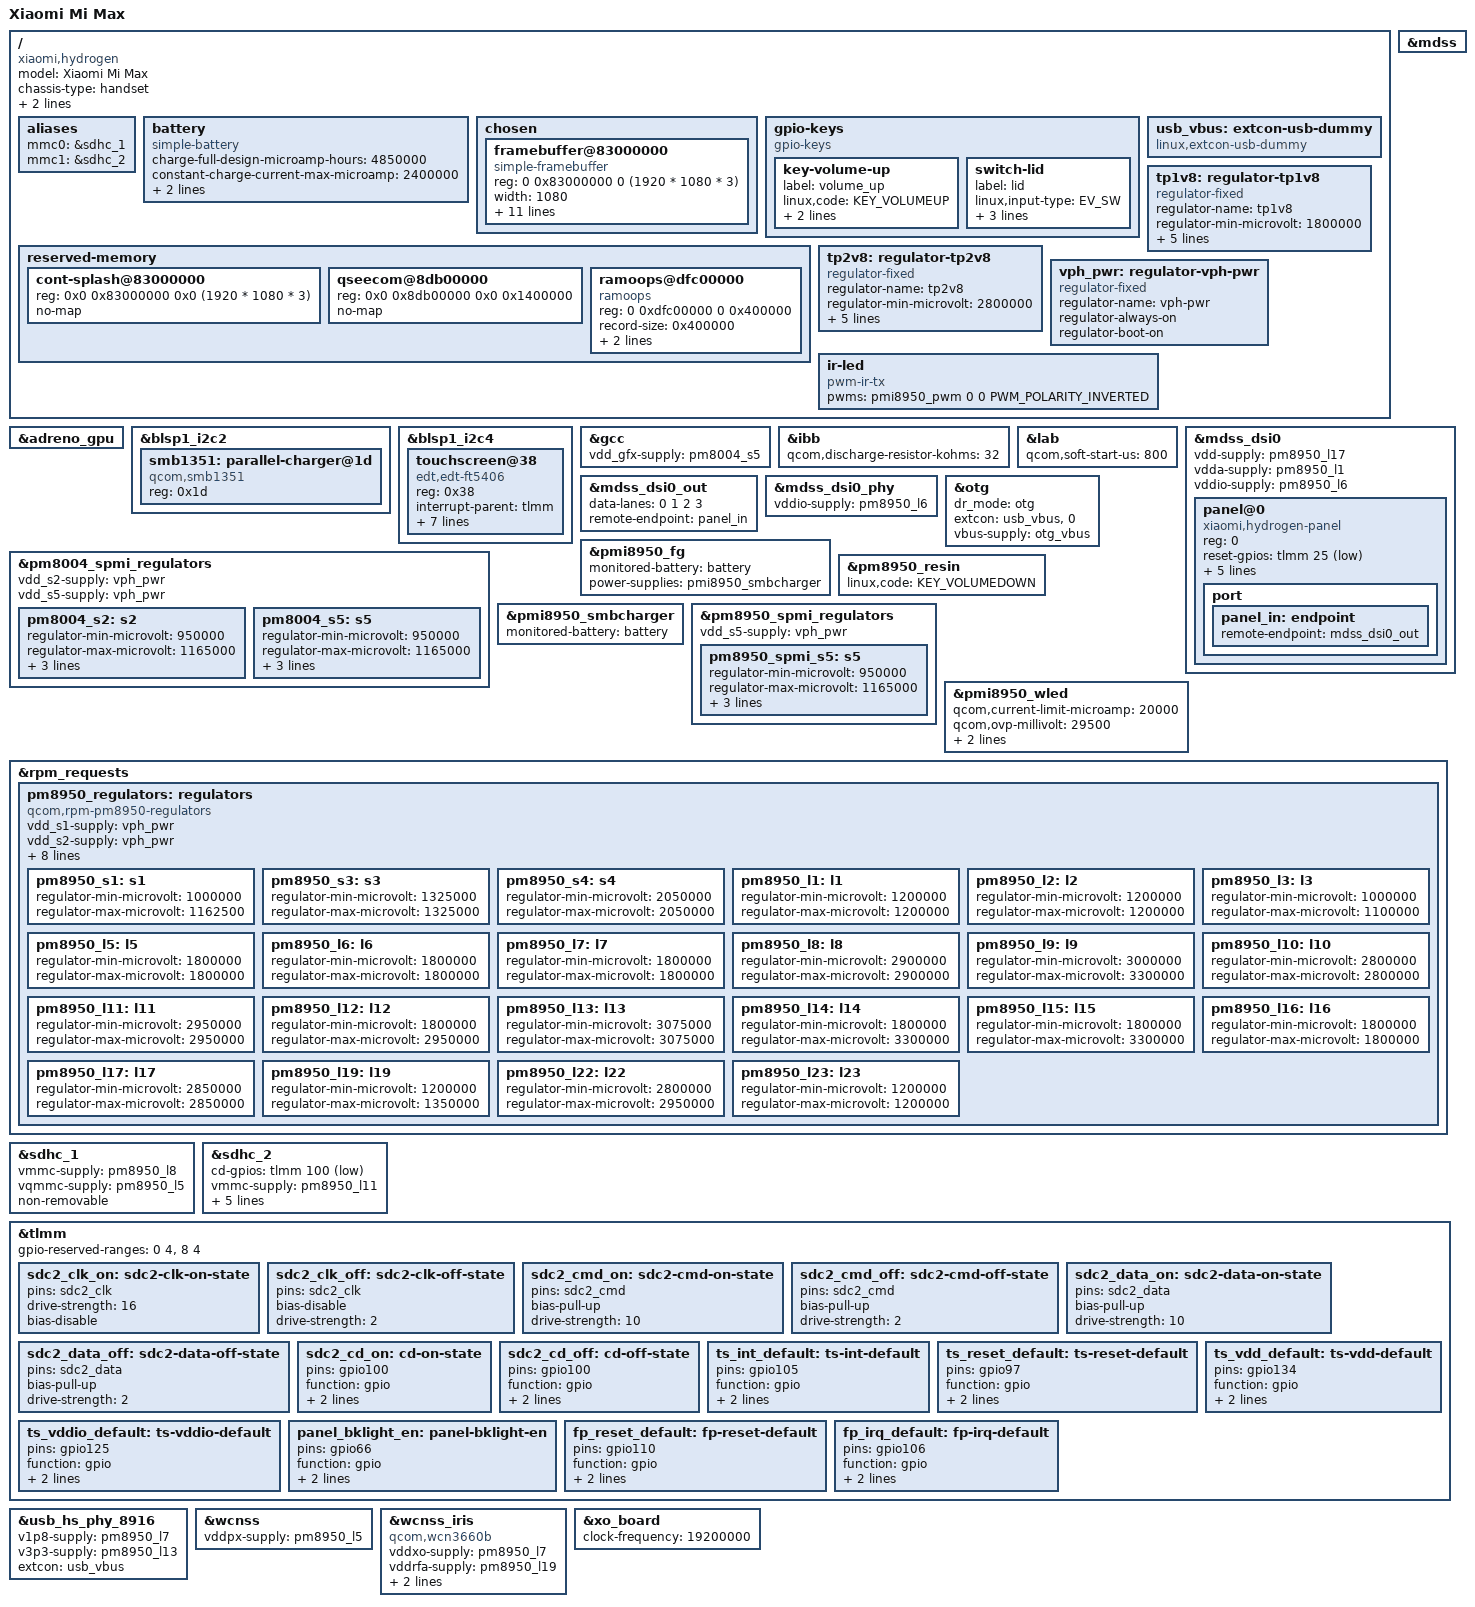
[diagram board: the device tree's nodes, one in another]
// SPDX-License-Identifier: BSD-3-Clause
/*
 * Copyright (c) 2024, Barnabas Czeman <trabarni@gmail.com>
 * Copyright (c) 2026, Jamie Chio <chioks03@gmail.com>
 *
 * Based on msm8956-xiaomi-kenzo.dts, adapted from hydrogen downstream DTS.
 *
 * Xiaomi Mi Max (hydrogen) hardware overview:
 *   - SoC: Qualcomm MSM8956 (Snapdragon 650)
 *   - PMIC: PM8950 + PMI8950 + PM8004
 *   - Display: 1080x1920 6.44" IPS (Tianma R63350 / AUO R61322)
 *   - Touch: Atmel mXT336U / FocalTech FT5x46 (I2C4)
 *   - Battery: 4850 mAh (ATL / Coslight)
 *   - Storage: eMMC + microSD
 *   - WiFi/BT: Qualcomm WCN3660b
 *   - Fingerprint: FPC FPC1020
 *   - Notification LED: Awinic AW2013 RGB (I2C8)
 *   - Hall sensor: GPIO 107
 */
/dts-v1/;

#include <dt-bindings/arm/qcom,ids.h>
#include <dt-bindings/input/atmel-maxtouch.h>
#include <dt-bindings/input/input.h>
#include <dt-bindings/pwm/pwm.h>

#include "msm8956.dtsi"

#include "pm8004.dtsi"
#include "pm8950.dtsi"
#include "pmi8950.dtsi"

/ {
	model = "Xiaomi Mi Max";
	compatible = "xiaomi,hydrogen", "qcom,msm8956";
	chassis-type = "handset";
	qcom,msm-id = <QCOM_ID_MSM8956 0x10001>;
	qcom,board-id = <QCOM_BOARD_ID_MTP 0>;

	aliases {
		mmc0 = &sdhc_1;
		mmc1 = &sdhc_2;
	};

	battery: battery {
		compatible = "simple-battery";

		/* ATL/Coslight 4850 mAh packs */
		charge-full-design-microamp-hours = <4850000>;
		constant-charge-current-max-microamp = <2400000>;
		voltage-min-design-microvolt = <3400000>;
		voltage-max-design-microvolt = <4400000>;
	};

	    chosen {
		#address-cells = <2>;
		#size-cells = <2>;
		ranges;

		/* Downstream cont_splash at 0x83000000 */
		framebuffer@83000000 {
		    compatible = "simple-framebuffer";
		    reg = <0 0x83000000 0 (1920 * 1080 * 3)>;

		    width = <1080>;
		    height = <1920>;
		    stride = <(1080 * 3)>;
		    format = "r8g8b8";

		    power-domains = <&gcc MDSS_GDSC>;

		    clocks = <&gcc GCC_MDSS_AHB_CLK>,
		         <&gcc GCC_MDSS_AXI_CLK>,
		         <&gcc GCC_MDSS_VSYNC_CLK>,
		         <&gcc GCC_MDSS_MDP_CLK>,
		         <&gcc GCC_MDSS_BYTE0_CLK>,
		         <&gcc GCC_MDSS_PCLK0_CLK>,
		         <&gcc GCC_MDSS_ESC0_CLK>;

		    status = "okay";
		};
	    };

	gpio-keys {
		compatible = "gpio-keys";

		key-volume-up {
			label = "volume_up";
			linux,code = <KEY_VOLUMEUP>;
			gpios = <&tlmm 113 GPIO_ACTIVE_LOW>;
			wakeup-source;
		};

		/* Hall / lid sensor (downstream gpio 107) */
		switch-lid {
			label = "lid";
			linux,input-type = <EV_SW>;
			linux,code = <SW_LID>;
			gpios = <&tlmm 107 GPIO_ACTIVE_LOW>;
			wakeup-source;
		};
	};

	reserved-memory {
		cont-splash@83000000 {
			reg = <0x0 0x83000000 0x0 (1920 * 1080 * 3)>;
			no-map;
		};

		/delete-node/ ext-region@85b00000;
		/delete-node/ tz-apps@8dd00000;
		/delete-node/ memory@8da00000;

		/* Hydrogen: qseecom/tzapp at 0x8db00000, 20 MiB (downstream) */
		qseecom@8db00000 {
			reg = <0x0 0x8db00000 0x0 0x1400000>;
			no-map;
		};

		ramoops@dfc00000 {
			compatible = "ramoops";
			reg = <0 0xdfc00000 0 0x400000>;
			record-size = <0x400000>;
			console-size = <0x200000>;
			pmsg-size = <0x200000>;
		};
	};

	usb_vbus: extcon-usb-dummy {
		compatible = "linux,extcon-usb-dummy";
	};

	/*
	 * Touch power rails (downstream tp1v8_vreg / tp2v8_vreg).
	 * Kenzo used a single GPIO LDO on 134; hydrogen has separate 1.8V and 2.8V.
	 */
	tp1v8: regulator-tp1v8 {
		compatible = "regulator-fixed";
		regulator-name = "tp1v8";
		regulator-min-microvolt = <1800000>;
		regulator-max-microvolt = <1800000>;
		enable-active-high;
		gpio = <&tlmm 125 GPIO_ACTIVE_HIGH>;
		startup-delay-us = <5000>;
		pinctrl-0 = <&ts_vddio_default>;
		pinctrl-names = "default";
	};

	tp2v8: regulator-tp2v8 {
		compatible = "regulator-fixed";
		regulator-name = "tp2v8";
		regulator-min-microvolt = <2800000>;
		regulator-max-microvolt = <2800000>;
		enable-active-high;
		gpio = <&tlmm 134 GPIO_ACTIVE_HIGH>;
		startup-delay-us = <5000>;
		pinctrl-0 = <&ts_vdd_default>;
		pinctrl-names = "default";
	};

	vph_pwr: regulator-vph-pwr {
		compatible = "regulator-fixed";
		regulator-name = "vph-pwr";
		regulator-always-on;
		regulator-boot-on;
	};

	/* IR Blaster via PMI8950 PWM (downstream pwm_ir) */
	ir-led {
		compatible = "pwm-ir-tx";
		pwms = <&pmi8950_pwm 0 0 PWM_POLARITY_INVERTED>;
	};
};

&adreno_gpu {
	status = "okay";
};

&blsp1_i2c2 {
	status = "okay";

	/* Parallel charger (downstream smb1351 at 0x1d) */
	smb1351: parallel-charger@1d {
		compatible = "qcom,smb1351";
		reg = <0x1d>;
	};
};

&blsp1_i2c4 {
    status = "okay";

    touchscreen@38 {
        compatible = "edt,edt-ft5406";
        reg = <0x38>;

        interrupt-parent = <&tlmm>;
        interrupts = <105 IRQ_TYPE_EDGE_FALLING>;

        vcc-supply = <&tp2v8>;    /* 2.8V rail */
        iovcc-supply = <&tp1v8>;  /* 1.8V rail */

        reset-gpios = <&tlmm 97 GPIO_ACTIVE_LOW>;

        pinctrl-names = "default";
        pinctrl-0 = <&ts_int_default &ts_reset_default>;

        touchscreen-size-x = <1080>;
        touchscreen-size-y = <1920>;
    };
};


/*
 * blsp1_i2c8 (AW2013 RGB notification LED) is disabled:
 * v6.18 msm8956.dtsi/msm8976.dtsi does not expose a blsp1_i2c8 node.
 * Re-enable once the bus is upstreamed.
 */
#if 0
&blsp1_i2c8 {
	status = "okay";

	/* AW2013 RGB notification LED (downstream 0x45) */
	aw2013: led-controller@45 {
		compatible = "awinic,aw2013";
		reg = <0x45>;
		vdd-supply = <&pm8950_l10>;
		vcc-supply = <&pm8950_l5>;

		#address-cells = <1>;
		#size-cells = <0>;

		led@0 {
			reg = <0>;
			label = "red";
			linux,default-trigger = "none";
		};

		led@1 {
			reg = <1>;
			label = "green";
			linux,default-trigger = "none";
		};

		led@2 {
					reg = <2>;
					label = "blue";
					linux,default-trigger = "none";
				};
			};
		};
		#endif

&gcc {
	vdd_gfx-supply = <&pm8004_s5>;
};

&ibb {
	qcom,discharge-resistor-kohms = <32>;
};

&lab {
	qcom,soft-start-us = <800>;
};

&mdss {
	status = "okay";
};

&mdss_dsi0 {
	vdd-supply = <&pm8950_l17>;
	vdda-supply = <&pm8950_l1>;
	vddio-supply = <&pm8950_l6>;

	status = "okay";

	panel@0 {
		compatible = "xiaomi,hydrogen-panel";
		reg = <0>;

		reset-gpios = <&tlmm 25 GPIO_ACTIVE_LOW>;
		/* Downstream: backlight enable on gpio66 (platform-bklight-en-gpio) */
		enable-gpios = <&tlmm 66 GPIO_ACTIVE_HIGH>;
		backlight = <&pmi8950_wled>;

		pinctrl-0 = <&panel_bklight_en>;
		pinctrl-names = "default";

		vsp-supply = <&lab>;
		vsn-supply = <&ibb>;

		port {
			panel_in: endpoint {
				remote-endpoint = <&mdss_dsi0_out>;
			};
		};
	};
};

&mdss_dsi0_out {
	data-lanes = <0 1 2 3>;
	remote-endpoint = <&panel_in>;
};

&mdss_dsi0_phy {
	vddio-supply = <&pm8950_l6>;
	status = "okay";
};

&otg {
    /* 1. Allow the controller to switch between host and peripheral */
    dr_mode = "otg";
    
    /* 2. Keep the dummy extcon to satisfy the dtsi, but it won't block DRD */
    extcon = <&usb_vbus>, <0>;
    
    /* 3. Supply 5V to the OTG port when in host mode */
    vbus-supply = <&otg_vbus>;
    
    status = "okay";
};

&pm8004_spmi_regulators {
	vdd_s2-supply = <&vph_pwr>;
	vdd_s5-supply = <&vph_pwr>;

	/* Cluster 1 supply */
	pm8004_s2: s2 {
		/* Set .95V to prevent unstabilities until CPR for this SoC is done */
		regulator-min-microvolt = <950000>;
		regulator-max-microvolt = <1165000>;
		regulator-name = "vdd_apc1";
		/* Set always on until the CPU PLL is done */
		regulator-always-on;
		regulator-boot-on;
	};

	pm8004_s5: s5 {
		regulator-min-microvolt = <950000>;
		regulator-max-microvolt = <1165000>;
		regulator-enable-ramp-delay = <500>;
		regulator-name = "vdd_gfx";
		/* Hack this on until the gpu driver is ready for it */
		regulator-always-on;
	};
};

/*
 * Button backlight on PM8004 MPP2 (downstream qcom,led_mpp_2).
 * Disabled: v6.18 pm8004.dtsi does not expose pm8004_mpps.
 */
#if 0
&pm8004_mpps {
	mpp@a100 {
		status = "okay";
		qcom,mode = <5>; /* Digital output */
		qcom,output-type = <0>; /* CMOS */
		qcom,pin-supply = <0>; /* VPH */
		qcom,master-en = <1>;
	};
};
#endif

&pmi8950_fg {
	monitored-battery = <&battery>;
	power-supplies = <&pmi8950_smbcharger>;
	status = "okay";
};

/* Haptic / vibrator motor (LRA type, downstream qcom,qpnp-haptic).
 * Disabled: v6.18 pmi8950.dtsi does not expose pmi8950_haptic. */
#if 0
&pmi8950_haptic {
	status = "okay";
};
#endif

&pm8950_resin {
	linux,code = <KEY_VOLUMEDOWN>;
	status = "okay";
};

&pmi8950_smbcharger {
	monitored-battery = <&battery>;
	status = "okay";
};

&pm8950_spmi_regulators {
	vdd_s5-supply = <&vph_pwr>;

	/* Cluster 0 supply */
	pm8950_spmi_s5: s5 {
		/* Set .95V to prevent unstabilities until CPR for this SoC is done */
		regulator-min-microvolt = <950000>;
		regulator-max-microvolt = <1165000>;
		regulator-name = "vdd_apc0";
		/* Set always on until the CPU PLL is done */
		regulator-always-on;
		regulator-boot-on;
	};
};

&pmi8950_wled {
	/* Downstream MTP: fs-curr 20 mA; CABC enabled; no external-pfet on hydrogen */
	qcom,current-limit-microamp = <20000>;
	qcom,ovp-millivolt = <29500>;
	qcom,num-strings = <2>;
	qcom,enable-cabc;

	status = "okay";
};

&rpm_requests {
	pm8950_regulators: regulators {
		compatible = "qcom,rpm-pm8950-regulators";

		vdd_s1-supply = <&vph_pwr>;
		vdd_s2-supply = <&vph_pwr>;
		vdd_s3-supply = <&vph_pwr>;
		vdd_s4-supply = <&vph_pwr>;
		vdd_s6-supply = <&vph_pwr>;
		vdd_l1_l19-supply = <&pm8950_s3>;
		vdd_l2_l23-supply = <&pm8950_s3>;
		vdd_l3-supply = <&pm8950_s3>;
		vdd_l5_l6_l7_l16-supply = <&pm8950_s4>;
		vdd_l8_l11_l12_l17_l22-supply = <&vph_pwr>;

		pm8950_s1: s1 {
			regulator-min-microvolt = <1000000>;
			regulator-max-microvolt = <1162500>;
		};

		pm8950_s3: s3 {
			regulator-min-microvolt = <1325000>;
			regulator-max-microvolt = <1325000>;
		};

		pm8950_s4: s4 {
			regulator-min-microvolt = <2050000>;
			regulator-max-microvolt = <2050000>;
		};

		pm8950_l1: l1 {
			regulator-min-microvolt = <1200000>;
			regulator-max-microvolt = <1200000>;
		};

		pm8950_l2: l2 {
			regulator-min-microvolt = <1200000>;
			regulator-max-microvolt = <1200000>;
		};

		pm8950_l3: l3 {
			regulator-min-microvolt = <1000000>;
			regulator-max-microvolt = <1100000>;
		};

		pm8950_l5: l5 {
			regulator-min-microvolt = <1800000>;
			regulator-max-microvolt = <1800000>;
		};

		pm8950_l6: l6 {
			regulator-min-microvolt = <1800000>;
			regulator-max-microvolt = <1800000>;
		};

		pm8950_l7: l7 {
			regulator-min-microvolt = <1800000>;
			regulator-max-microvolt = <1800000>;
		};

		pm8950_l8: l8 {
			regulator-min-microvolt = <2900000>;
			regulator-max-microvolt = <2900000>;
		};

		pm8950_l9: l9 {
			regulator-min-microvolt = <3000000>;
			regulator-max-microvolt = <3300000>;
		};

		pm8950_l10: l10 {
			regulator-min-microvolt = <2800000>;
			regulator-max-microvolt = <2800000>;
		};

		pm8950_l11: l11 {
			regulator-min-microvolt = <2950000>;
			regulator-max-microvolt = <2950000>;
		};

		pm8950_l12: l12 {
			regulator-min-microvolt = <1800000>;
			regulator-max-microvolt = <2950000>;
		};

		pm8950_l13: l13 {
			regulator-min-microvolt = <3075000>;
			regulator-max-microvolt = <3075000>;
		};

		pm8950_l14: l14 {
			regulator-min-microvolt = <1800000>;
			regulator-max-microvolt = <3300000>;
		};

		pm8950_l15: l15 {
			regulator-min-microvolt = <1800000>;
			regulator-max-microvolt = <3300000>;
		};

		pm8950_l16: l16 {
			regulator-min-microvolt = <1800000>;
			regulator-max-microvolt = <1800000>;
		};

		pm8950_l17: l17 {
			regulator-min-microvolt = <2850000>;
			regulator-max-microvolt = <2850000>;
		};

		pm8950_l19: l19 {
			regulator-min-microvolt = <1200000>;
			regulator-max-microvolt = <1350000>;
		};

		pm8950_l22: l22 {
			regulator-min-microvolt = <2800000>;
			regulator-max-microvolt = <2950000>;
		};

		pm8950_l23: l23 {
			regulator-min-microvolt = <1200000>;
			regulator-max-microvolt = <1200000>;
		};
	};
};


&sdhc_1 {
	vmmc-supply = <&pm8950_l8>;
	vqmmc-supply = <&pm8950_l5>;
	non-removable;

	status = "okay";
};

&sdhc_2 {
	cd-gpios = <&tlmm 100 GPIO_ACTIVE_LOW>;
	vmmc-supply = <&pm8950_l11>;
	vqmmc-supply = <&pm8950_l12>;

	pinctrl-0 = <&sdc2_clk_on &sdc2_cmd_on &sdc2_data_on &sdc2_cd_on>;
	pinctrl-1 = <&sdc2_clk_off &sdc2_cmd_off &sdc2_data_off &sdc2_cd_off>;
	pinctrl-names = "default", "sleep";

	status = "okay";
};

&tlmm {
	gpio-reserved-ranges = <0 4>, <8 4>;

	sdc2_clk_on: sdc2-clk-on-state {
		pins = "sdc2_clk";
		drive-strength = <16>;
		bias-disable;
	};

	sdc2_clk_off: sdc2-clk-off-state {
		pins = "sdc2_clk";
		bias-disable;
		drive-strength = <2>;
	};

	sdc2_cmd_on: sdc2-cmd-on-state {
		pins = "sdc2_cmd";
		bias-pull-up;
		drive-strength = <10>;
	};

	sdc2_cmd_off: sdc2-cmd-off-state {
		pins = "sdc2_cmd";
		bias-pull-up;
		drive-strength = <2>;
	};

	sdc2_data_on: sdc2-data-on-state {
		pins = "sdc2_data";
		bias-pull-up;
		drive-strength = <10>;
	};

	sdc2_data_off: sdc2-data-off-state {
		pins = "sdc2_data";
		bias-pull-up;
		drive-strength = <2>;
	};

	sdc2_cd_on: cd-on-state {
		pins = "gpio100";
		function = "gpio";
		drive-strength = <2>;
		bias-pull-up;
	};

	sdc2_cd_off: cd-off-state {
		pins = "gpio100";
		function = "gpio";
		drive-strength = <2>;
		bias-disable;
	};

	/* Touch IRQ: hydrogen gpio105 (kenzo used gpio65) */
	ts_int_default: ts-int-default {
		pins = "gpio105";
		function = "gpio";
		drive-strength = <8>;
		bias-pull-up;
	};

	/* Touch reset: hydrogen gpio97 (kenzo used gpio64) */
	ts_reset_default: ts-reset-default {
		pins = "gpio97";
		function = "gpio";
		drive-strength = <8>;
		bias-pull-up;
	};

	/* Touch 1.8V enable (gpio125) */
	ts_vddio_default: ts-vddio-default {
		pins = "gpio125";
		function = "gpio";
		drive-strength = <2>;
		bias-disable;
	};

	/* Touch 2.8V enable (gpio134) */
	ts_vdd_default: ts-vdd-default {
		pins = "gpio134";
		function = "gpio";
		drive-strength = <16>;
		bias-pull-up;
	};

	/* Panel backlight enable (downstream gpio66) */
	panel_bklight_en: panel-bklight-en {
		pins = "gpio66";
		function = "gpio";
		drive-strength = <8>;
		bias-disable;
	};

	/* Fingerprint sensor pins (FPC1020: reset 110, irq 106) */
	fp_reset_default: fp-reset-default {
		pins = "gpio110";
		function = "gpio";
		drive-strength = <8>;
		bias-pull-up;
	};

	fp_irq_default: fp-irq-default {
		pins = "gpio106";
		function = "gpio";
		drive-strength = <8>;
		bias-pull-up;
	};
};

&usb_hs_phy_8916 {
	v1p8-supply = <&pm8950_l7>;
	v3p3-supply = <&pm8950_l13>;
	extcon = <&usb_vbus>;
	status = "okay";
};


&wcnss {
	vddpx-supply = <&pm8950_l5>;
	status = "okay";
};

&wcnss_iris {
	compatible = "qcom,wcn3660b";
	vddxo-supply = <&pm8950_l7>;
	vddrfa-supply = <&pm8950_l19>;
	vddpa-supply = <&pm8950_l9>;
	vdddig-supply = <&pm8950_l5>;
	status = "okay";
};

&xo_board {
	clock-frequency = <19200000>;
};
